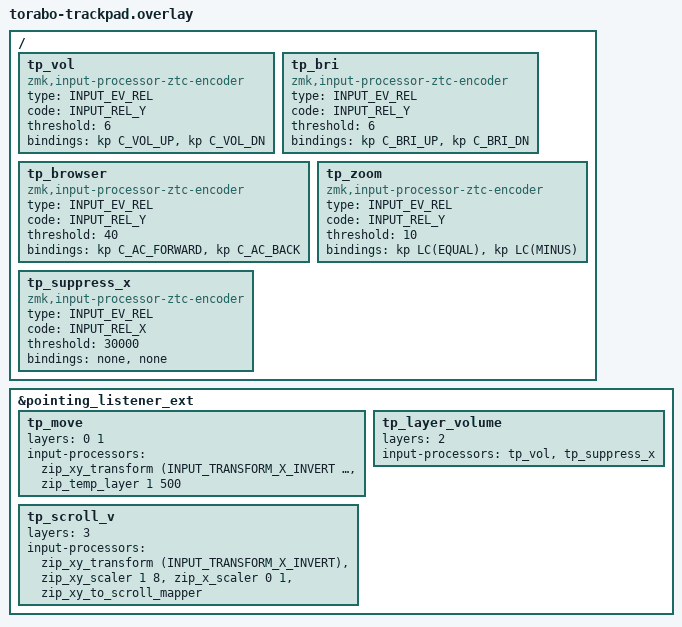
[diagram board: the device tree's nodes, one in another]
/*
 * torabo-trackpad — per-layer FUNCTION assignment for the extender mini trackpad.
 *
 * Apply AFTER input-trackpad-ext (it modifies that snippet's pointing_listener_ext):
 *   -S "... input-trackpad-ext torabo-trackpad"
 * (with input-trackpad-ext-diy too if the pad is the self-made one).
 *
 * The mini pad is effectively a 1-axis (vertical) control, so beyond scroll/move
 * we turn a swipe into discrete key TAPS via &ztc_encoder: it accumulates one
 * axis and every `threshold` units taps the +/- behavior (splitting by sign).
 * Everything is FIXED per layer here (rebuild to change) — no BLE/GATT.
 *
 * Edit the per-layer children below to taste. Each encoder is a small node with
 * two bindings <positive> <negative>; ready-made ones (volume/brightness/browser/
 * zoom) are defined at the bottom. `tp_suppress_x` swallows sideways motion so a
 * discrete layer stays purely vertical.
 */

#include <dt-bindings/zmk/keys.h>
#include <dt-bindings/zmk/input_transform.h>
#include <zephyr/dt-bindings/input/input-event-codes.h>

&pointing_listener_ext {
    /delete-node/ scroll_vertical;
    /delete-node/ scroll_horizontal;
    /delete-node/ mouse_mode;

    /* layers 0,1 — cursor move (same as stock) */
    tp_move {
        layers = <0 1>;
        input-processors = <&zip_xy_transform (INPUT_TRANSFORM_X_INVERT | INPUT_TRANSFORM_Y_INVERT)>, <&zip_temp_layer 1 500>;
    };

    /* layer 2 — volume up/down (vertical swipe) */
    tp_layer_volume {
        layers = <2>;
        input-processors = <&tp_vol>, <&tp_suppress_x>;
    };

    /* layer 3 — vertical scroll (same as stock) */
    tp_scroll_v {
        layers = <3>;
        input-processors = <&zip_xy_transform (INPUT_TRANSFORM_X_INVERT)>, <&zip_xy_scaler 1 8>, <&zip_x_scaler 0 1>, <&zip_xy_to_scroll_mapper>;
    };

    /* Examples — assign to spare layers as desired:
     * tp_layer_brightness { layers = <4>; input-processors = <&tp_bri>, <&tp_suppress_x>; };
     * tp_layer_browser    { layers = <5>; input-processors = <&tp_browser>, <&tp_suppress_x>; };
     * tp_layer_zoom       { layers = <6>; input-processors = <&tp_zoom>, <&tp_suppress_x>; };
     */
};

/ {
    /* Encoder instances: <positive(up/forward)>, <negative(down/back)>.
     * threshold = swipe units per tap (bigger = coarser / needs a longer swipe). */
    tp_vol: tp_vol {
        compatible = "zmk,input-processor-ztc-encoder";
        #input-processor-cells = <0>;
        type = <INPUT_EV_REL>;
        code = <INPUT_REL_Y>;
        threshold = <6>;
        bindings = <&kp C_VOL_UP>, <&kp C_VOL_DN>;
    };

    tp_bri: tp_bri {
        compatible = "zmk,input-processor-ztc-encoder";
        #input-processor-cells = <0>;
        type = <INPUT_EV_REL>;
        code = <INPUT_REL_Y>;
        threshold = <6>;
        bindings = <&kp C_BRI_UP>, <&kp C_BRI_DN>;
    };

    /* Browser back/forward: large threshold => ~one action per swipe (one-shot). */
    tp_browser: tp_browser {
        compatible = "zmk,input-processor-ztc-encoder";
        #input-processor-cells = <0>;
        type = <INPUT_EV_REL>;
        code = <INPUT_REL_Y>;
        threshold = <40>;
        bindings = <&kp C_AC_FORWARD>, <&kp C_AC_BACK>;
    };

    /* Zoom in/out = Ctrl+= / Ctrl+- (encoder taps). */
    tp_zoom: tp_zoom {
        compatible = "zmk,input-processor-ztc-encoder";
        #input-processor-cells = <0>;
        type = <INPUT_EV_REL>;
        code = <INPUT_REL_Y>;
        threshold = <10>;
        bindings = <&kp LC(EQUAL)>, <&kp LC(MINUS)>;
    };

    /* Swallow sideways (X) motion so a discrete layer stays purely vertical.
     * &none taps do nothing; the encoder just consumes REL_X. */
    tp_suppress_x: tp_suppress_x {
        compatible = "zmk,input-processor-ztc-encoder";
        #input-processor-cells = <0>;
        type = <INPUT_EV_REL>;
        code = <INPUT_REL_X>;
        threshold = <30000>; /* effectively never taps; just consumes REL_X */
        bindings = <&none>, <&none>;
    };
};
